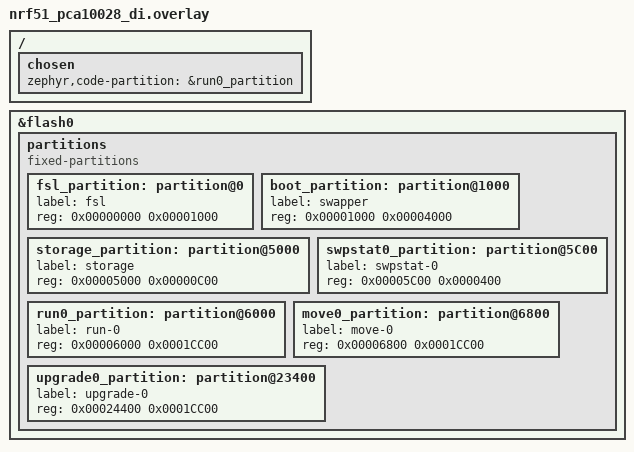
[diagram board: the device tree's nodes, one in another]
/*
 * Copyright (c) 2019 Laczen
 *
 * Overlay file for ZB-8 dual image setup
 *
 * SPDX-License-Identifier: Apache-2.0
 */

/delete-node/ &boot_partition;
/delete-node/ &scratch_partition;
/delete-node/ &slot0_partition;
/delete-node/ &slot1_partition;
/delete-node/ &storage_partition;

/ {
	chosen {
		zephyr,code-partition = &run0_partition;
	};
};

&flash0 {
	/*
	 * For more information, see:
	 * http://docs.zephyrproject.org/latest/guides/dts/index.html#flash-partitions
	 */
	partitions {
		compatible = "fixed-partitions";
		#address-cells = <1>;
		#size-cells = <1>;

		fsl_partition: partition@0 {
			label = "fsl";
			reg = <0x00000000 0x00001000>;
		};
		boot_partition: partition@1000 {
			label = "swapper";
			reg = <0x00001000 0x00004000>;
		};
		storage_partition: partition@5000 {
			label = "storage";
			reg = <0x00005000 0x00000C00>;
		};
		swpstat0_partition: partition@5C00 {
			label = "swpstat-0";
			reg = <0x00005C00 0x0000400>;
		};
		run0_partition: partition@6000 {
			label = "run-0";
			reg = <0x00006000 0x0001CC00>;
		};
		move0_partition: partition@6800 {
			label = "move-0";
			reg = <0x00006800 0x0001CC00>;
		};
		upgrade0_partition: partition@23400 {
			label = "upgrade-0";
			reg = <0x00024400 0x0001CC00>;
		};
	};
};
